# AT32F421 register map
Vendor: Keil; Series: AT32F421; File version: 1.0
CPU: CM4 r0p1, little endian, no MPU, FPU, 4 interrupt priority bits
Registers are 32-bit, read-write, reset 0x0 unless marked. A register's access mark holds for its fields unless they carry their own. Offsets are from the block's base; [hi:lo] are bit positions; {n}, {i} and the like mark numbered series.

## WWDT — Window watchdog
Base 0x40002C00
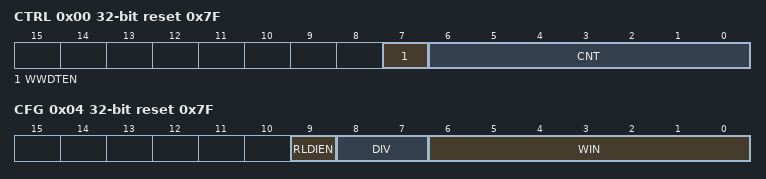
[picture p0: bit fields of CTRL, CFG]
0x00 CTRL reset 0x7F — Control register
  [7] WWDTEN write-1-sets — Window watchdog enable
    on read: 0=Disabled; 1=Enabled | on write: 1=Enable
  [6:0] CNT — Decrement counter
0x04 CFG reset 0x7F — Configuration register
  [9] RLDIEN — Reload counter interrupt
    on read: 0=Disabled; 1=Enabled | on write: 0=Disable; 1=Enable
  [8:7] DIV — Clock division value
    0=PCLK1 divided by 4096; 1=PCLK1 divided by 8192; 2=PCLK1 divided by 16384; 3=PCLK1 divided by 32768
  [6:0] WIN — Window value
0x08 STS — Status register
  [0] RLDF write-0-clears — Reload counter interrupt flag
    on read: 0=NotReached (Downcounter doesn't reached 0x40); 1=Reached (Downcounter reached 0x40) | on write: 0=Clear flag

## TMR6 — Basic timer
Base 0x40001000
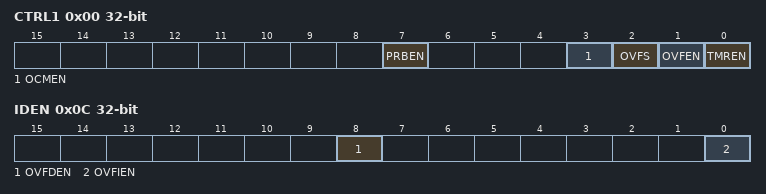
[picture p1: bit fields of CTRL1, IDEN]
0x00 CTRL1 — Control register 1
  [7] PRBEN — Period buffer enable
    on read: 0=Disabled (Period buffer is disabled); 1=Enabled (Period buffer is enabled) | on write: 0=Disable (Period buffer disable); 1=Enable (Period buffer enable)
  [3] OCMEN — One cycle mode enable
    0=Continuous (The counter does not stop at an update event); 1=OneCycle (The counter stops at an update event)
  [2] OVFS — Overflow event source
    0=Any (Counter overflow, setting the OVFSWTR bit or overflow event generated by slave timer controller); 1=Counter (Only counter overflow generates an overflow event)
  [1] OVFEN — Overflow event enable
    on read: 0=Disabled (Overflow is disabled); 1=Enabled (Overflow is enabled) | on write: 0=Disable (Overflow disable); 1=Enable (Overflow enable)
  [0] TMREN — TMR enable
    on read: 0=Disabled (Timer is disabled); 1=Enabled (Timer is enabled) | on write: 0=Disable (Timer disable); 1=Enable (Timer enable)
0x04 CTRL2 — Control register 2
  [6:4] PTOS — Primary TMR output selection
    0=Reset; 1=Enable; 2=Update; 3=ComparePulse; {v}=C{v-3}ORAW (C{v-3}ORAW signal) (v=4..7)
0x0C IDEN — Interrupt/DMA enable register
  [8] OVFDEN — Overflow DMA request enable
    on read: 0=Disabled (Overflow event DMA request is disabled); 1=Enabled (Overflow event DMA request is enabled) | on write: 0=Disable (Overflow event DMA request disable); 1=Enable (Overflow event DMA request enable)
  [0] OVFIEN — Overflow interrupt enable
    on read: 0=Disabled (Overflow interrupt is disabled); 1=Enabled (Overflow interrupt is enabled) | on write: 0=Disable (Overflow interrupt disable); 1=Enable (Overflow interrupt enable)
0x10 ISTS — Interrupt status register
  [0] OVFIF write-0-clears — Overflow interrupt flag
    on read: 0=No overflow event occurs; 1=Overflow (An overflow event is generated) | on write: 0=Clear (Overflow interrupt flag clear)
0x14 SWEVT — Software event register
  [0] OVFSWTR write-1-sets — Overflow event triggered by software
    on write: 1=Overflow (Generate an overflow event)
0x24 CVAL 16-bit — Counter value
0x28 DIV 16-bit — Divider value
0x2C PR 16-bit — Period value

## CMP — Comparator
Base 0x4001001C
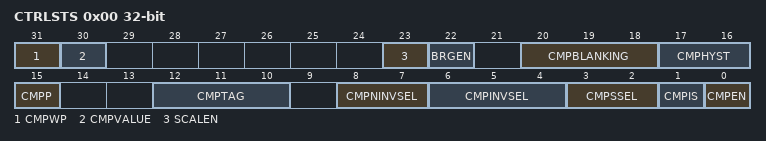
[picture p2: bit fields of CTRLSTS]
0x00 CTRLSTS — CMP control/status register
  [31] CMPWP — Comparator write protect
  [30] CMPVALUE ro — Comparator output value
  [23] SCALEN — Comparator scalen
  [22] BRGEN — Comparator brgen
  [20:18] CMPBLANKING — Comparator blanking
  [17:16] CMPHYST — Comparator hysteresis
  [15] CMPP — Comparator polarity
  [12:10] CMPTAG — Comparator output target
  [8:7] CMPNINVSEL — Comparator non-inverting input selection
  [6:4] CMPINVSEL — Comparator inverting selection
  [3:2] CMPSSEL — Comparator speed selection
  [1] CMPIS — Comparator input shift
  [0] CMPEN — Comparator enable bit
0x08 G_FILTER_EN
  [0] GFE — Glitch filter enable
0x0C HIGH_PULSE
  [5:0] H_PULSE_CNT — High pulse Count
0x10 LOW_PULSE
  [5:0] L_PULSE_CNT — Low pulse Count
